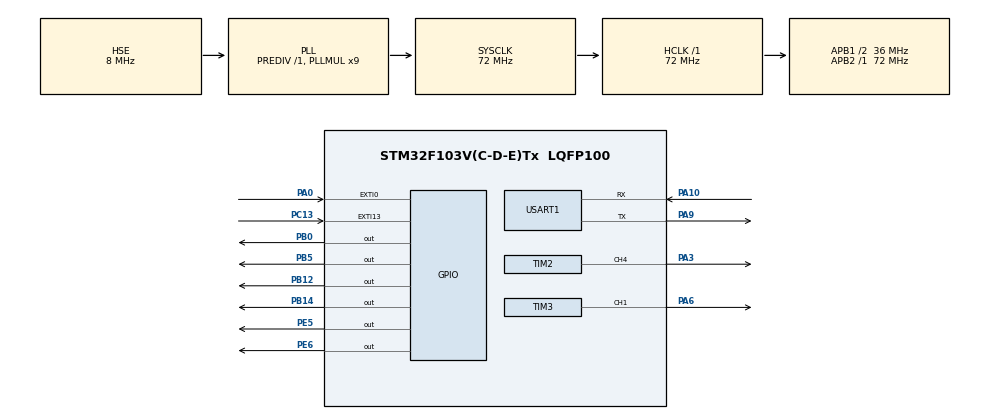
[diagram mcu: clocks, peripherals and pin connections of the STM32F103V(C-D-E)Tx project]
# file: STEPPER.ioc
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Mcu.Family=STM32F1
Mcu.Name=STM32F103V(C-D-E)Tx
Mcu.Package=LQFP100
NVIC.EXTI0_IRQn=true\:0\:0\:false\:false\:true\:true\:true
NVIC.EXTI15_10_IRQn=true\:0\:0\:false\:false\:true\:true\:true
NVIC.PriorityGroup=NVIC_PRIORITYGROUP_4
NVIC.TIM2_IRQn=true\:0\:0\:false\:false\:true\:true\:true
NVIC.TIM3_IRQn=true\:0\:0\:false\:false\:true\:true\:true
NVIC.USART1_IRQn=true\:0\:0\:false\:false\:true\:true\:true
OSC_IN.Mode=HSE-External-Oscillator
OSC_IN.Signal=RCC_OSC_IN
OSC_OUT.Mode=HSE-External-Oscillator
OSC_OUT.Signal=RCC_OSC_OUT
PA0-WKUP.Signal=GPXTI0
PA10.Mode=Asynchronous
PA10.Signal=USART1_RX
PA13.Mode=Serial_Wire
PA13.Signal=SYS_JTMS-SWDIO
PA14.Mode=Serial_Wire
PA14.Signal=SYS_JTCK-SWCLK
PA3.Signal=S_TIM2_CH4
PA6.Signal=S_TIM3_CH1
PA9.Mode=Asynchronous
PA9.Signal=USART1_TX
PB0.Signal=GPIO_Output
PB12.Signal=GPIO_Output
PB14.Signal=GPIO_Output
PB5.Signal=GPIO_Output
PC13-TAMPER-RTC.Signal=GPXTI13
PE5.Signal=GPIO_Output
PE6.Signal=GPIO_Output
ProjectManager.HeapSize=0x200
ProjectManager.StackSize=0x400
ProjectManager.TargetToolchain=MDK-ARM V5
RCC.AHBFreq_Value=72000000
RCC.APB1CLKDivider=RCC_HCLK_DIV2
RCC.APB1Freq_Value=36000000
RCC.APB1TimFreq_Value=72000000
RCC.APB2Freq_Value=72000000
RCC.APB2TimFreq_Value=72000000
RCC.HCLKFreq_Value=72000000
RCC.PLLMUL=RCC_PLL_MUL9
RCC.PLLSourceVirtual=RCC_PLLSOURCE_HSE
RCC.SYSCLKFreq_VALUE=72000000
RCC.SYSCLKSource=RCC_SYSCLKSOURCE_PLLCLK
RCC.USBFreq_Value=72000000
SH.S_TIM2_CH4.0=TIM2_CH4,PWM Generation4 CH4
SH.S_TIM3_CH1.0=TIM3_CH1,PWM Generation1 CH1
TIM2.Channel-PWM\ Generation4\ CH4=TIM_CHANNEL_4
TIM2.Period=1000-1
TIM2.Prescaler=72-1
TIM2.Pulse-PWM\ Generation4\ CH4=500
TIM3.Channel-PWM\ Generation1\ CH1=TIM_CHANNEL_1
TIM3.Period=1000-1
TIM3.Prescaler=72-1
TIM3.Pulse-PWM\ Generation1\ CH1=500
USART1.VirtualMode=VM_ASYNC
VP_TIM2_VS_ClockSourceINT.Mode=Internal
VP_TIM3_VS_ClockSourceINT.Mode=Internal
board=custom

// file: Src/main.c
/* USER CODE BEGIN Header */
/**
  ******************************************************************************
  * @file           : main.c
  * @brief          : Main program body
  ******************************************************************************
  * @attention
  *
  * <h2><center>&copy; Copyright (c) 2022 STMicroelectronics.
  * All rights reserved.</center></h2>
  *
  * This software component is licensed by ST under BSD 3-Clause license,
  * the "License"; You may not use this file except in compliance with the
  * License. You may obtain a copy of the License at:
  *                        opensource.org/licenses/BSD-3-Clause
  *
  ******************************************************************************
  */
/* USER CODE END Header */

#include "main.h"
#include "tim.h"
#include "usart.h"
#include "gpio.h"
#include "test.h"
#include "micostep.h"

/* USER CODE BEGIN PD */

/**
  * @brief          外部中断回调函数
  * @param[in]      pvParameters: GPIO_PIN_5 or GPIO_PIN_
  * @retval         none
  */
 void HAL_GPIO_EXTI_Callback(uint16_t GPIO_Pin)
{
  /* Prevent unused argument(s) compilation warning */
  UNUSED(GPIO_Pin);
  /* NOTE: This function Should not be modified, when the callback is needed,
           the HAL_GPIO_EXTI_Callback could be implemented in the user file
   */
	if(GPIO_Pin==KEY1_PIN)
	{
		//指示灯亮红灯，此时电机可以被手扭动
		GREEN_OFF;
		RED_ON;
		SMD1_ENA(DISABLE);
		SMD2_ENA(DISABLE);
	}
	else
	{
		//指示灯亮绿灯，此时电机处于上电状态
		GREEN_ON;
		RED_OFF;
		SMD1_ENA(ENABLE);
		SMD2_ENA(ENABLE);
	}
}

/* USER CODE END PD */

void SystemClock_Config(void);

int main(void)
{

  /* MCU Configuration--------------------------------------------------------*/

  /* Reset of all peripherals, Initializes the Flash interface and the Systick. */
  HAL_Init();

  /* Configure the system clock */
  SystemClock_Config();

  /* Initialize all configured peripherals */
  MX_GPIO_Init();
  MX_TIM2_Init();
  MX_USART1_UART_Init();
  MX_TIM3_Init();

  /* Infinite loop */
  while (1)
  {
		DealSerialData();

  }
}

void SystemClock_Config(void)
{
  RCC_OscInitTypeDef RCC_OscInitStruct = {0};
  RCC_ClkInitTypeDef RCC_ClkInitStruct = {0};

  /** Initializes the CPU, AHB and APB busses clocks
  */
  RCC_OscInitStruct.OscillatorType = RCC_OSCILLATORTYPE_HSE;
  RCC_OscInitStruct.HSEState = RCC_HSE_ON;
  RCC_OscInitStruct.HSEPredivValue = RCC_HSE_PREDIV_DIV1;
  RCC_OscInitStruct.HSIState = RCC_HSI_ON;
  RCC_OscInitStruct.PLL.PLLState = RCC_PLL_ON;
  RCC_OscInitStruct.PLL.PLLSource = RCC_PLLSOURCE_HSE;
  RCC_OscInitStruct.PLL.PLLMUL = RCC_PLL_MUL9;
  if (HAL_RCC_OscConfig(&RCC_OscInitStruct) != HAL_OK)
  {
    Error_Handler();
  }
  /** Initializes the CPU, AHB and APB busses clocks
  */
  RCC_ClkInitStruct.ClockType = RCC_CLOCKTYPE_HCLK|RCC_CLOCKTYPE_SYSCLK
                              |RCC_CLOCKTYPE_PCLK1|RCC_CLOCKTYPE_PCLK2;
  RCC_ClkInitStruct.SYSCLKSource = RCC_SYSCLKSOURCE_PLLCLK;
  RCC_ClkInitStruct.AHBCLKDivider = RCC_SYSCLK_DIV1;
  RCC_ClkInitStruct.APB1CLKDivider = RCC_HCLK_DIV2;
  RCC_ClkInitStruct.APB2CLKDivider = RCC_HCLK_DIV1;

  if (HAL_RCC_ClockConfig(&RCC_ClkInitStruct, FLASH_LATENCY_2) != HAL_OK)
  {
    Error_Handler();
  }
}

void Error_Handler(void)
{
}

/************************ (C) COPYRIGHT STMicroelectronics *****END OF FILE****/
